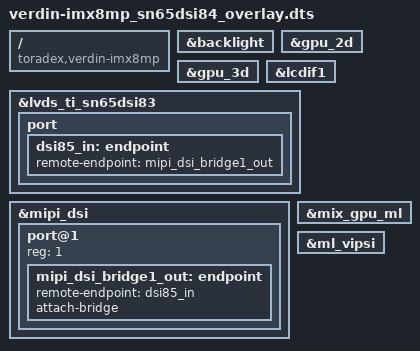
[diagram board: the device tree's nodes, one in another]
// SPDX-License-Identifier: GPL-2.0-or-later OR MIT
/*
 * Copyright 2020-2021 Toradex
 */

// Verdin DSI to LVDS Adapter orderable at Toradex.

/dts-v1/;
/plugin/;

/ {
	compatible = "toradex,verdin-imx8mp";
};

&backlight {
	status = "okay";
};

&gpu_2d {
	status = "okay";
};

&gpu_3d {
	status = "okay";
};

/* LCDIF to MIPI-DSI */
&lcdif1 {
	status = "okay";
};

&lvds_ti_sn65dsi83 {
	status = "okay";

	port {
		dsi85_in: endpoint {
			remote-endpoint = <&mipi_dsi_bridge1_out>;
		};
	};
};

&mipi_dsi {
	#address-cells = <1>;
	#size-cells = <0>;
	status = "okay";

	port@1 {
		reg = <1>;

		mipi_dsi_bridge1_out: endpoint {
			remote-endpoint = <&dsi85_in>;
			attach-bridge;
		};
	};
};

&mix_gpu_ml {
	status = "okay";
};

&ml_vipsi {
	status = "okay";
};
